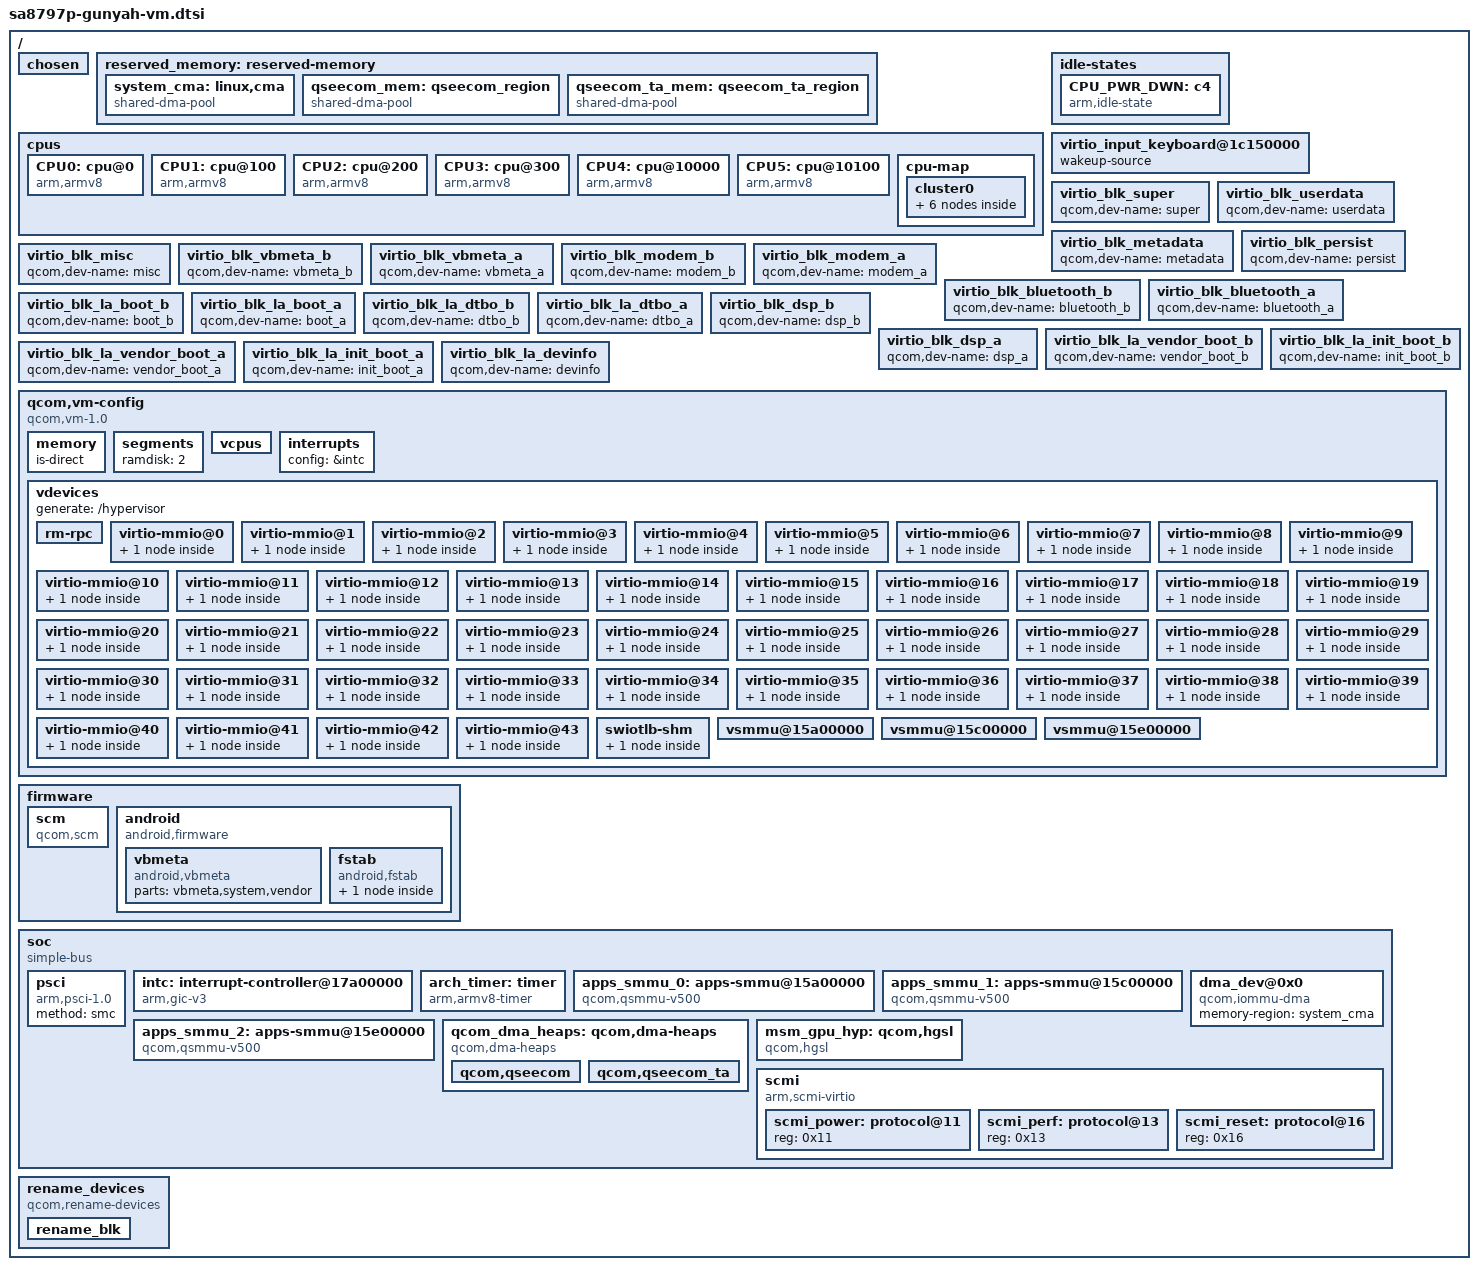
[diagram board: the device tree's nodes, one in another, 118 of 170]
#include <dt-bindings/interrupt-controller/arm-gic.h>
#include <dt-bindings/arm/msm/qcom_dma_heap_dt_constants.h>
/ {
	#address-cells = <0x2>;
	#size-cells = <0x2>;
	qcom,msm-id = <690 0x10000>, <690 0x20000>;
	interrupt-parent = <&intc>;

	chosen {
		bootargs = "console=hvc0 root=/dev/ram rw rootwait nokaslr log_buf_len=1M androidboot.force_normal_boot=1 ufshcd-core.use_mcq_mode=n kpti=0 loglevel=8 printk.devkmsg=on maxcpus=6 androidboot.verifiedbootstate=orange";
	};

	reserved_memory: reserved-memory {
		#address-cells = <2>;
		#size-cells = <2>;
		ranges;

		system_cma: linux,cma {
			compatible = "shared-dma-pool";
			alloc-ranges = <0x0 0x0 0x0 0xffffffff>;
			reusable;
			alignment = <0x0 0x400000>;
			size = <0x0 0x2000000>;
			linux,cma-default;
		};

		qseecom_mem: qseecom_region {
			compatible = "shared-dma-pool";
			alloc-ranges = <0x0 0x00000000 0x0 0xffffffff>;
			reusable;
			alignment = <0x0 0x400000>;
			size = <0x0 0x1400000>;
		};

		qseecom_ta_mem: qseecom_ta_region {
			compatible = "shared-dma-pool";
			alloc-ranges = <0x0 0x00000000 0x0 0xffffffff>;
			reusable;
			alignment = <0x0 0x400000>;
			size = <0x0 0x1000000>;
		};
	};

	cpus {
		#address-cells = <0x2>;
		#size-cells = <0x0>;

		CPU0: cpu@0 {
			compatible = "arm,armv8";
			reg = <0x0 0x0>;
			device_type = "cpu";
			enable-method = "psci";
			cpu-idle-states = <&CPU_PWR_DWN>;
		};

		CPU1: cpu@100 {
			compatible = "arm,armv8";
			reg = <0x0 0x100>;
			device_type = "cpu";
			enable-method = "psci";
			cpu-idle-states = <&CPU_PWR_DWN>;
		};

		CPU2: cpu@200 {
			compatible = "arm,armv8";
			reg = <0x0 0x200>;
			device_type = "cpu";
			enable-method = "psci";
			cpu-idle-states = <&CPU_PWR_DWN>;
		};

		CPU3: cpu@300 {
			compatible = "arm,armv8";
			reg = <0x0 0x300>;
			device_type = "cpu";
			enable-method = "psci";
			cpu-idle-states = <&CPU_PWR_DWN>;
		};

		CPU4: cpu@10000 {
			compatible = "arm,armv8";
			reg = <0x0 0x400>;
			device_type = "cpu";
			enable-method = "psci";
			cpu-idle-states = <&CPU_PWR_DWN>;
		};

		CPU5: cpu@10100 {
			compatible = "arm,armv8";
			reg = <0x0 0x500>;
			device_type = "cpu";
			enable-method = "psci";
			cpu-idle-states = <&CPU_PWR_DWN>;
		};

		cpu-map {
			cluster0 {
				core0 {
					cpu = <&CPU0>;
				};

				core1 {
					cpu = <&CPU1>;
				};

				core2 {
					cpu = <&CPU2>;
				};

				core3 {
					cpu = <&CPU3>;
				};

				core4 {
					cpu = <&CPU4>;
				};

				core5 {
					cpu = <&CPU5>;
				};
			};
		};
	};

	idle-states {
		CPU_PWR_DWN: c4 { /* C4 */
			compatible = "arm,idle-state";
			idle-state-name = "rail-pc";
			entry-latency-us = <702>;
			exit-latency-us = <1061>;
			min-residency-us = <4488>;
			arm,psci-suspend-param = <0x40000004>;
			local-timer-stop;
		};
	};

	virtio_input_keyboard@1c150000 {
		wakeup-source;
	};

	virtio_blk_super {
		qcom,dev-name = "super";
	};

	virtio_blk_userdata {
		qcom,dev-name = "userdata";
	};

	virtio_blk_metadata {
		qcom,dev-name = "metadata";
	};

	virtio_blk_persist {
		qcom,dev-name = "persist";
	};

	virtio_blk_misc {
		qcom,dev-name = "misc";
	};

	virtio_blk_vbmeta_b {
		qcom,dev-name = "vbmeta_b";
	};

	virtio_blk_vbmeta_a {
		qcom,dev-name = "vbmeta_a";
	};

	virtio_blk_modem_b {
		qcom,dev-name = "modem_b";
	};

	virtio_blk_modem_a {
		qcom,dev-name = "modem_a";
	};

	virtio_blk_bluetooth_b {
		qcom,dev-name = "bluetooth_b";
	};

	virtio_blk_bluetooth_a {
		qcom,dev-name = "bluetooth_a";
	};

	virtio_blk_la_boot_b {
		qcom,dev-name = "boot_b";
	};

	virtio_blk_la_boot_a {
		qcom,dev-name = "boot_a";
	};

	virtio_blk_la_dtbo_b {
		qcom,dev-name = "dtbo_b";
	};

	virtio_blk_la_dtbo_a {
		qcom,dev-name = "dtbo_a";
	};

	virtio_blk_dsp_b {
		qcom,dev-name = "dsp_b";
	};

	virtio_blk_dsp_a {
		qcom,dev-name = "dsp_a";
	};

	virtio_blk_la_vendor_boot_b {
		qcom,dev-name = "vendor_boot_b";
	};

	virtio_blk_la_vendor_boot_a {
		qcom,dev-name = "vendor_boot_a";
	};

	virtio_blk_la_init_boot_b {
		qcom,dev-name = "init_boot_b";
	};

	virtio_blk_la_init_boot_a {
		qcom,dev-name = "init_boot_a";
	};

	virtio_blk_la_devinfo {
		qcom,dev-name = "devinfo";
	};

	qcom,vm-config {
		compatible = "qcom,vm-1.0";
		vm-type = "aarch64-guest";
		boot-config = "fdt,unified";
		os-type = "linux";
		kernel-entry-segment = "kernel";
		kernel-entry-offset = <0x0 0x0>;
		vendor = "QTI";
		image-name = "qcom,autoghgvm";
		qcom,pasid = <0x0 0x2c>;
		qcom,qtee-config-info = "p=3,16,57,77,78,7A,7C,8F,97,159,199,47E,7F1,10C;";
		qcom,secdomain-ids = <52>;
		qcom,primary-vm-index = <0>;
		vm-attrs = "guest-ram-dump";

		memory {
			#address-cells = <0x2>;
			#size-cells = <0x0>;

			/* The IPA of the Guest regions is placed as IPA=PA */
			is-direct;
		};

		segments {
			ramdisk = <2>;
		};

		vcpus {
			config = "/cpus";
			affinity = "static";
			affinity-map = <0x5 0x4 0x3 0x2 0x1 0x0>;
			sched-priority = <0>;       /* relative to PVM */
			sched-timeslice = <5000>;   /* in ms */
		};

		interrupts {
			config = &intc;
		};

		vdevices {
			generate = "/hypervisor";

			rm-rpc {
				vdevice-type = "rm-rpc";
				generate = "/hypervisor/qcom,resource-mgr";
				console-dev;
				message-size = <0x000000f0>;
				queue-depth = <0x00000008>;
				qcom,label = <0x1>;
			};

			virtio-mmio@0 {
				vdevice-type = "virtio-mmio";
				generate = "/virtio-mmio";
				peer-default;
				vqs-num = <0x1>;
				push-compatible = "virtio,mmio";
				sync-reset;
				dma-coherent;
				dma_base = <0x0 0x0>;
				memory {
					qcom,label = <0x20>;
					#address-cells = <0x2>;
					allocate-base;
				};
			};

			virtio-mmio@1 {
				vdevice-type = "virtio-mmio";
				patch = "/virtio_blk_la_devinfo";
				peer-default;
				vqs-num = <0x1>;
				push-compatible = "virtio,mmio";
				sync-reset;
				dma-coherent;
				dma_base = <0x0 0x4000>;
				memory {
					qcom,label = <0x21>;
					#address-cells = <0x2>;
					allocate-base;
				};
			};

			virtio-mmio@2 {
				vdevice-type = "virtio-mmio";
				patch = "/virtio_blk_la_init_boot_a";
				peer-default;
				vqs-num = <0x1>;
				push-compatible = "virtio,mmio";
				sync-reset;
				dma-coherent;
				dma_base = <0x0 0x8000>;
				memory {
					qcom,label = <0x22>;
					#address-cells = <0x2>;
					allocate-base;
				};
			};

			virtio-mmio@3 {
				vdevice-type = "virtio-mmio";
				patch = "/virtio_blk_la_init_boot_b";
				peer-default;
				vqs-num = <0x1>;
				push-compatible = "virtio,mmio";
				sync-reset;
				dma-coherent;
				dma_base = <0x0 0xC000>;
				memory {
					qcom,label = <0x23>;
					#address-cells = <0x2>;
					allocate-base;
				};
			};

			virtio-mmio@4 {
				vdevice-type = "virtio-mmio";
				patch = "/virtio_blk_la_vendor_boot_a";
				peer-default;
				vqs-num = <0x1>;
				push-compatible = "virtio,mmio";
				sync-reset;
				dma-coherent;
				dma_base = <0x0 0x10000>;
				memory {
					qcom,label = <0x24>;
					#address-cells = <0x2>;
					allocate-base;
				};
			};

			virtio-mmio@5 {
				vdevice-type = "virtio-mmio";
				patch = "/virtio_blk_la_vendor_boot_b";
				peer-default;
				vqs-num = <0x1>;
				push-compatible = "virtio,mmio";
				sync-reset;
				dma-coherent;
				dma_base = <0x0 0x14000>;
				memory {
					qcom,label = <0x25>;
					#address-cells = <0x2>;
					allocate-base;
				};
			};

			virtio-mmio@6 {
				vdevice-type = "virtio-mmio";
				patch = "/virtio_blk_dsp_a";
				peer-default;
				vqs-num = <0x1>;
				push-compatible = "virtio,mmio";
				sync-reset;
				dma-coherent;
				dma_base = <0x0 0x18000>;
				memory {
					qcom,label = <0x26>;
					#address-cells = <0x2>;
					allocate-base;
				};
			};

			virtio-mmio@7 {
				vdevice-type = "virtio-mmio";
				patch = "/virtio_blk_dsp_b";
				peer-default;
				vqs-num = <0x1>;
				push-compatible = "virtio,mmio";
				sync-reset;
				dma-coherent;
				dma_base = <0x0 0x1C000>;
				memory {
					qcom,label = <0x27>;
					#address-cells = <0x2>;
					allocate-base;
				};
			};

			virtio-mmio@8 {
				vdevice-type = "virtio-mmio";
				patch = "/virtio_blk_la_dtbo_a";
				peer-default;
				vqs-num = <0x1>;
				push-compatible = "virtio,mmio";
				sync-reset;
				dma-coherent;
				dma_base = <0x0 0x20000>;
				memory {
					qcom,label = <0x28>;
					#address-cells = <0x2>;
					allocate-base;
				};
			};

			virtio-mmio@9 {
				vdevice-type = "virtio-mmio";
				patch = "/virtio_blk_la_dtbo_b";
				peer-default;
				vqs-num = <0x1>;
				push-compatible = "virtio,mmio";
				sync-reset;
				dma-coherent;
				dma_base = <0x0 0x24000>;
				memory {
					qcom,label = <0x29>;
					#address-cells = <0x2>;
					allocate-base;
				};
			};

			virtio-mmio@10 {
				vdevice-type = "virtio-mmio";
				patch = "/virtio_blk_la_boot_a";
				peer-default;
				vqs-num = <0x1>;
				push-compatible = "virtio,mmio";
				sync-reset;
				dma-coherent;
				dma_base = <0x0 0x28000>;
				memory {
					qcom,label = <0x2A>;
					#address-cells = <0x2>;
					allocate-base;
				};
			};

			virtio-mmio@11 {
				vdevice-type = "virtio-mmio";
				patch = "/virtio_blk_la_boot_b";
				peer-default;
				vqs-num = <0x1>;
				push-compatible = "virtio,mmio";
				sync-reset;
				dma-coherent;
				dma_base = <0x0 0x2C000>;
				memory {
					qcom,label = <0x2B>;
					#address-cells = <0x2>;
					allocate-base;
				};
			};

			virtio-mmio@12 {
				vdevice-type = "virtio-mmio";
				patch = "/virtio_blk_bluetooth_a";
				peer-default;
				vqs-num = <0x1>;
				push-compatible = "virtio,mmio";
				sync-reset;
				dma-coherent;
				dma_base = <0x0 0x30000>;
				memory {
					qcom,label = <0x2C>;
					#address-cells = <0x2>;
					allocate-base;
				};
			};

			virtio-mmio@13 {
				vdevice-type = "virtio-mmio";
				patch = "/virtio_blk_bluetooth_b";
				peer-default;
				vqs-num = <0x1>;
				push-compatible = "virtio,mmio";
				sync-reset;
				dma-coherent;
				dma_base = <0x0 0x34000>;
				memory {
					qcom,label = <0x2D>;
					#address-cells = <0x2>;
					allocate-base;
				};
			};

			virtio-mmio@14 {
				vdevice-type = "virtio-mmio";
				patch = "/virtio_blk_modem_a";
				peer-default;
				vqs-num = <0x1>;
				push-compatible = "virtio,mmio";
				sync-reset;
				dma-coherent;
				dma_base = <0x0 0x38000>;
				memory {
					qcom,label = <0x2E>;
					#address-cells = <0x2>;
					allocate-base;
				};
			};

			virtio-mmio@15 {
				vdevice-type = "virtio-mmio";
				patch = "/virtio_blk_modem_b";
				peer-default;
				vqs-num = <0x1>;
				push-compatible = "virtio,mmio";
				sync-reset;
				dma-coherent;
				dma_base = <0x0 0x3C000>;
				memory {
					qcom,label = <0x2F>;
					#address-cells = <0x2>;
					allocate-base;
				};
			};

			virtio-mmio@16 {
				vdevice-type = "virtio-mmio";
				patch = "/virtio_blk_vbmeta_a";
				peer-default;
				vqs-num = <0x1>;
				push-compatible = "virtio,mmio";
				sync-reset;
				dma-coherent;
				dma_base = <0x0 0x40000>;
				memory {
					qcom,label = <0x30>;
					#address-cells = <0x2>;
					allocate-base;
				};
			};

			virtio-mmio@17 {
				vdevice-type = "virtio-mmio";
				patch = "/virtio_blk_vbmeta_b";
				peer-default;
				vqs-num = <0x1>;
				push-compatible = "virtio,mmio";
				sync-reset;
				dma-coherent;
				dma_base = <0x0 0x44000>;
				memory {
					qcom,label = <0x31>;
					#address-cells = <0x2>;
					allocate-base;
				};
			};

			virtio-mmio@18 {
				vdevice-type = "virtio-mmio";
				patch = "/virtio_blk_misc";
				peer-default;
				vqs-num = <0x1>;
				push-compatible = "virtio,mmio";
				sync-reset;
				dma-coherent;
				dma_base = <0x0 0x48000>;
				memory {
					qcom,label = <0x32>;
					#address-cells = <0x2>;
					allocate-base;
				};
			};

			virtio-mmio@19 {
				vdevice-type = "virtio-mmio";
				patch = "/virtio_blk_persist";
				peer-default;
				vqs-num = <0x1>;
				push-compatible = "virtio,mmio";
				sync-reset;
				dma-coherent;
				dma_base = <0x0 0x4C000>;
				memory {
					qcom,label = <0x33>;
					#address-cells = <0x2>;
					allocate-base;
				};
			};

			virtio-mmio@20 {
				vdevice-type = "virtio-mmio";
				patch = "/virtio_blk_metadata";
				peer-default;
				vqs-num = <0x1>;
				push-compatible = "virtio,mmio";
				sync-reset;
				dma-coherent;
				dma_base = <0x0 0x50000>;
				memory {
					qcom,label = <0x34>;
					#address-cells = <0x2>;
					allocate-base;
				};
			};

			virtio-mmio@21 {
				vdevice-type = "virtio-mmio";
				patch = "/virtio_blk_userdata";
				peer-default;
				vqs-num = <0x1>;
				push-compatible = "virtio,mmio";
				sync-reset;
				dma-coherent;
				dma_base = <0x0 0x54000>;
				memory {
					qcom,label = <0x35>;
					#address-cells = <0x2>;
					allocate-base;
				};
			};

			virtio-mmio@22 {
				vdevice-type = "virtio-mmio";
				patch = "/virtio_blk_super";
				peer-default;
				vqs-num = <0x1>;
				push-compatible = "virtio,mmio";
				sync-reset;
				dma-coherent;
				dma_base = <0x0 0x58000>;
				memory {
					qcom,label = <0x36>;
					#address-cells = <0x2>;
					allocate-base;
				};
			};

			/* Virtio net 0 device */
			virtio-mmio@23 {
				vdevice-type = "virtio-mmio";
				generate = "/virtio-mmio";
				peer-default;
				vqs-num = <0x2>;
				push-compatible = "virtio,mmio";
				sync-reset;
				dma-coherent;
				dma_base = <0x0 0x5C000>;
				memory {
					qcom,label = <0x37>;
					#address-cells = <0x2>;
					allocate-base;
				};
			};

			/* Virtio net 1 device */
			virtio-mmio@24 {
				vdevice-type = "virtio-mmio";
				generate = "/virtio-mmio";
				peer-default;
				vqs-num = <0x2>;
				push-compatible = "virtio,mmio";
				sync-reset;
				dma-coherent;
				dma_base = <0x0 0x64000>;
				memory {
					qcom,label = <0x38>;
					#address-cells = <0x2>;
					allocate-base;
				};
			};

			/* HAB 0 device */
			virtio-mmio@25 {
				vdevice-type = "virtio-mmio";
				generate = "/virtio-mmio";
				peer-default;
				vqs-num = <0x2>;
				push-compatible = "virtio,mmio";
				sync-reset;
				dma-coherent;
				dma_base = <0x0 0x6C000>;
				memory {
					qcom,label = <0x39>;
					#address-cells = <0x2>;
					allocate-base;
				};
			};

			/* HAB 1 device */
			virtio-mmio@26 {
				vdevice-type = "virtio-mmio";
				generate = "/virtio-mmio";
				peer-default;
				vqs-num = <0x2>;
				push-compatible = "virtio,mmio";
				sync-reset;
				dma-coherent;
				dma_base = <0x0 0x7C000>;
				memory {
					qcom,label = <0x3A>;
					#address-cells = <0x2>;
					allocate-base;
				};
			};

			/* HAB 2 device */
			virtio-mmio@27 {
				vdevice-type = "virtio-mmio";
				generate = "/virtio-mmio";
				peer-default;
				vqs-num = <0x8>;
				push-compatible = "virtio,mmio";
				sync-reset;
				dma-coherent;
				dma_base = <0x0 0x8C000>;
				memory {
					qcom,label = <0x3B>;
					#address-cells = <0x2>;
					allocate-base;
				};
			};

			/* HAB 3 device */
			virtio-mmio@28 {
				vdevice-type = "virtio-mmio";
				generate = "/virtio-mmio";
				peer-default;
				vqs-num = <0xA>;
				push-compatible = "virtio,mmio";
				sync-reset;
				dma-coherent;
				dma_base = <0x0 0xCC000>;
				memory {
					qcom,label = <0x3C>;
					#address-cells = <0x2>;
					allocate-base;
				};
			};

			/* HAB 4 device */
			virtio-mmio@29 {
				vdevice-type = "virtio-mmio";
				generate = "/virtio-mmio";
				peer-default;
				vqs-num = <0x6>;
				push-compatible = "virtio,mmio";
				sync-reset;
				dma-coherent;
				dma_base = <0x0 0x11C000>;
				memory {
					qcom,label = <0x3D>;
					#address-cells = <0x2>;
					allocate-base;
				};
			};

			/* HAB 5 device */
			virtio-mmio@30 {
				vdevice-type = "virtio-mmio";
				generate = "/virtio-mmio";
				peer-default;
				vqs-num = <0x6>;
				push-compatible = "virtio,mmio";
				sync-reset;
				dma-coherent;
				dma_base = <0x0 0x14C000>;
				memory {
					qcom,label = <0x3E>;
					#address-cells = <0x2>;
					allocate-base;
				};
			};

			/* Virtio input 0 device */
			virtio-mmio@31 {
				vdevice-type = "virtio-mmio";
				generate = "/virtio-mmio";
				virtio,device-type = <18>;
				peer-default;
				vqs-num = <0x2>;
				push-compatible = "virtio,mmio";
				sync-reset;
				dma-coherent;
				dma_base = <0x0 0x17C000>;
				memory {
					qcom,label = <0x3F>;
					#address-cells = <0x2>;
					allocate-base;
				};
			};

			/* Virtio input 1 device */
			virtio-mmio@32 {
				vdevice-type = "virtio-mmio";
				generate = "/virtio-mmio";
				virtio,device-type = <18>;
				peer-default;
				vqs-num = <0x2>;
				push-compatible = "virtio,mmio";
				sync-reset;
				dma-coherent;
				dma_base = <0x0 0x180000>;
				memory {
					qcom,label = <0x40>;
					#address-cells = <0x2>;
					allocate-base;
				};
			};

			/* Virtio console device */
			virtio-mmio@33 {
				vdevice-type = "virtio-mmio";
				generate = "/virtio-mmio";
				peer-default;
				vqs-num = <0x2>;
				push-compatible = "virtio,mmio";
				sync-reset;
				dma-coherent;
				dma_base = <0x0 0x184000>;
				memory {
					qcom,label = <0x41>;
					#address-cells = <0x2>;
					allocate-base;
				};
			};

			/* Virtio SCMI device */
			virtio-mmio@34 {
				vdevice-type = "virtio-mmio";
				generate = "/virtio-mmio";
				peer-default;
				vqs-num = <0x2>;
				push-compatible = "virtio,mmio";
				sync-reset;
				dma-coherent;
				dma_base = <0x0 0x18C000>;
				memory {
					qcom,label = <0x42>;
					#address-cells = <0x2>;
					allocate-base;
				};
			};

			/* Virtio vsock device */
			virtio-mmio@35 {
				vdevice-type = "virtio-mmio";
				generate = "/virtio-mmio";
				peer-default;
				vqs-num = <0x3>;
				push-compatible = "virtio,mmio";
				sync-reset;
				dma-coherent;
				dma_base = <0x0 0x194000>;
				memory {
					qcom,label = <0x43>;
					#address-cells = <0x2>;
					allocate-base;
				};
			};

			/* Virtio glink device */
			virtio-mmio@36 {
				vdevice-type = "virtio-mmio";
				generate = "/virtio-mmio";
				peer-default;
				vqs-num = <0x1>;
				push-compatible = "virtio,mmio";
				sync-reset;
				dma-coherent;
				dma_base = <0x0 0x1A0000>;
				memory {
					qcom,label = <0x44>;
					#address-cells = <0x2>;
					allocate-base;
				};
			};

			/* Virtio FastRPC device */
			virtio-mmio@37 {
				vdevice-type = "virtio-mmio";
				generate = "/virtio-mmio";
				peer-default;
				vqs-num = <0x2>;
				push-compatible = "virtio,mmio";
				sync-reset;
				dma-coherent;
				dma_base = <0x0 0x1A2000>;
				memory {
					qcom,label = <0x45>;
					#address-cells = <0x2>;
					allocate-base;
				};
			};

			/* Virtio I2C device */
			virtio-mmio@38 {
				vdevice-type = "virtio-mmio";
				generate = "/virtio-mmio";
				peer-default;
				vqs-num = <0x1>;
				push-compatible = "virtio,mmio";
				sync-reset;
				dma-coherent;
				dma_base = <0x0 0x1A6000>;
				memory {
					qcom,label = <0x46>;
					#address-cells = <0x2>;
					allocate-base;
				};
			};

			/* Virtio SSR device */
			virtio-mmio@39 {
				vdevice-type = "virtio-mmio";
				generate = "/virtio-mmio";
				peer-default;
				vqs-num = <0x1>;
				push-compatible = "virtio,mmio";
				sync-reset;
				dma-coherent;
				dma_base = <0x0 0x1A8000>;
				memory {
					qcom,label = <0x47>;
					#address-cells = <0x2>;
					allocate-base;
				};
			};

			/* VHAB 6 device */
			virtio-mmio@40 {
				vdevice-type = "virtio-mmio";
				generate = "/virtio-mmio";
				peer-default;
				vqs-num = <0x2>;
				push-compatible = "virtio,mmio";
				sync-reset;
				dma-coherent;
				dma_base = <0x0 0x1AA000>;
				memory {
					qcom,label = <0x48>;
					#address-cells = <0x2>;
					allocate-base;
				};
			};

			/* VHAB 7 device */
			virtio-mmio@41 {
				vdevice-type = "virtio-mmio";
				generate = "/virtio-mmio";
				peer-default;
				vqs-num = <0x2>;
				push-compatible = "virtio,mmio";
				sync-reset;
				dma-coherent;
				dma_base = <0x0 0x1BA000>;
				memory {
					qcom,label = <0x49>;
					#address-cells = <0x2>;
					allocate-base;
				};
			};

			/* VHAB 8 device */
			virtio-mmio@42 {
				vdevice-type = "virtio-mmio";
				generate = "/virtio-mmio";
				peer-default;
				vqs-num = <0x6>;
				push-compatible = "virtio,mmio";
				sync-reset;
				dma-coherent;
				dma_base = <0x0 0x1CA000>;
				memory {
					qcom,label = <0x4A>;
					#address-cells = <0x2>;
					allocate-base;
				};
			};
			/* Reserved device */
			virtio-mmio@43 {
				vdevice-type = "virtio-mmio";
				generate = "/virtio-mmio";
				peer-default;
				vqs-num = <0x2>;
				push-compatible = "virtio,mmio";
				sync-reset;
				dma-coherent;
				dma_base = <0x0 0x1A0000>;
				memory {
					qcom,label = <0x4B>;
					#address-cells = <0x2>;
					allocate-base;
				};
			};

			swiotlb-shm {
				vdevice-type = "shm";
				generate = "/swiotlb";
				push-compatible = "swiotlb";
				peer-default;
				dma_base = <0x0 0x200000>;
				memory {
					qcom,label = <0x50>;
					#address-cells = <0x2>;
					allocate-base;
				};
			};

			vsmmu@15a00000 {
				vdevice-type = "vsmmu-v2";
				smmu-handle = <0x15a00000>;
				num-cbs = <0x8>;
				num-smrs = <0x8>;
				patch = "/soc/apps-smmu@15a00000";
			};

			vsmmu@15c00000 {
				vdevice-type = "vsmmu-v2";
				smmu-handle = <0x15c00000>;
				num-cbs = <0x8>;
				num-smrs = <0x8>;
				patch = "/soc/apps-smmu@15c00000";
			};

			vsmmu@15e00000 {
				vdevice-type = "vsmmu-v2";
				smmu-handle = <0x15e00000>;
				num-cbs = <0x8>;
				num-smrs = <0x8>;
				patch = "/soc/apps-smmu@15e00000";
			};
		};
	};

	firmware: firmware {
		scm {
			compatible = "qcom,scm";
		};

		android {
			compatible = "android,firmware";
			boot_devices = "70002000.virtio_blk_la_devinfo,70003000.virtio_blk_la_init_boot_a,70004000.virtio_blk_la_init_boot_b,70005000.virtio_blk_la_vendor_boot_a,70006000.virtio_blk_la_vendor_boot_b,70007000.virtio_blk_dsp_a,70008000.virtio_blk_dsp_b,70009000.virtio_blk_la_dtbo_a,7000a000.virtio_blk_la_dtbo_b,7000b000.virtio_blk_la_boot_a,7000c000.virtio_blk_la_boot_b,7000d000.virtio_blk_bluetooth_a,7000e000.virtio_blk_bluetooth_b,7000f000.virtio_blk_modem_a,70010000.virtio_blk_modem_b,70011000.virtio_blk_vbmeta_a,70012000.virtio_blk_vbmeta_b,70013000.virtio_blk_misc,70014000.virtio_blk_persist,70015000.virtio_blk_metadata,70016000.virtio_blk_userdata,70017000.virtio_blk_super";

			vbmeta {
				compatible = "android,vbmeta";
				parts = "vbmeta,system,vendor";
			};

			fstab {
				compatible = "android,fstab";
				vendor {
					compatible = "android,vendor";
					dev="/dev/block/platform/vdevs/1c0f0000.virtio_blk/vdc";
					type = "ext4";
					mnt_flags = "ro,barrier=1,discard";
					fsmgr_flags = "wait";
					status = "disabled";
				};
			};
		};
	};

	soc: soc { };
};

&soc {
	#address-cells = <1>;
	#size-cells = <1>;
	ranges = <0 0 0 0xffffffff>;
	compatible = "simple-bus";

	psci {
		compatible = "arm,psci-1.0";
		method = "smc";
	};

	intc: interrupt-controller@17a00000 {
		compatible = "arm,gic-v3";
		interrupt-controller;
		#interrupt-cells = <0x3>;
		#redistributor-regions = <1>;
		redistributor-stride = <0x0 0x20000>;
		reg = <0x17a00000 0x10000>,     /* GICD */
		      <0x17a60000 0x100000>;    /* GICR * 8 */
	};

	arch_timer: timer {
		compatible = "arm,armv8-timer";
		always-on;
		interrupts = <GIC_PPI 13 (GIC_CPU_MASK_SIMPLE(8) | IRQ_TYPE_LEVEL_LOW)>,
			     <GIC_PPI 14 (GIC_CPU_MASK_SIMPLE(8) | IRQ_TYPE_LEVEL_LOW)>,
			     <GIC_PPI 11 (GIC_CPU_MASK_SIMPLE(8) | IRQ_TYPE_LEVEL_LOW)>,
			     <GIC_PPI 12 (GIC_CPU_MASK_SIMPLE(8) | IRQ_TYPE_LEVEL_LOW)>;
		clock-frequency = <19200000>;
	};

	apps_smmu_0: apps-smmu@15a00000 {
		/*
		 * reg, #global-interrupts & interrupts  properties will
		 * be added dynamically by bootloader.
		 */
		compatible = "qcom,qsmmu-v500", "qcom,virt-smmu";
		#iommu-cells = <2>;
		qcom,use-3-lvl-tables;
		dma-coherent;
	};

	apps_smmu_1: apps-smmu@15c00000 {
		/*
		 * reg, #global-interrupts & interrupts  properties will
		 * be added dynamically by bootloader.
		 */
		compatible = "qcom,qsmmu-v500", "qcom,virt-smmu";
		#iommu-cells = <2>;
		qcom,use-3-lvl-tables;
		dma-coherent;
	};

	apps_smmu_2: apps-smmu@15e00000 {
		/*
		 * reg, #global-interrupts & interrupts  properties will
		 * be added dynamically by bootloader.
		 */
		compatible = "qcom,qsmmu-v500", "qcom,virt-smmu";
		#iommu-cells = <2>;
		qcom,use-3-lvl-tables;
		dma-coherent;
	};

	qcom_dma_heaps: qcom,dma-heaps {
		compatible = "qcom,dma-heaps";

		qcom,qseecom {
			qcom,dma-heap-name = "qcom,qseecom";
			qcom,dma-heap-type = <HEAP_TYPE_CMA>;
			memory-region = <&qseecom_mem>;
		};

		qcom,qseecom_ta {
			qcom,dma-heap-name = "qcom,qseecom-ta";
			qcom,dma-heap-type = <HEAP_TYPE_CMA>;
			memory-region = <&qseecom_ta_mem>;
		};
	};

	dma_dev@0x0 {
		compatible = "qcom,iommu-dma";
		memory-region = <&system_cma>;
	};

	msm_gpu_hyp: qcom,hgsl {
		compatible = "qcom,hgsl";

		default_iocoherency;
		db-off;
	};

	scmi {
		compatible = "arm,scmi-virtio";
		#address-cells = <1>;
		#size-cells = <0>;
		status = "ok";

		scmi_power: protocol@11 {
			reg = <0x11>;
			#power-domain-cells = <1>;
		};

		scmi_perf: protocol@13 {
			reg = <0x13>;
			#power-domain-cells = <1>;
		};

		scmi_reset: protocol@16 {
			reg = <0x16>;
			#reset-cells = <1>;
		};
	};
};

/ {
	rename_devices: rename_devices {
		compatible = "qcom,rename-devices";
		rename_blk: rename_blk {
			device-type = "block";
			actual-dev =    "vda", "vdb", "vdc",
					"vdd", "vde", "vdf",
					"vdg", "vdh", "vdi",
					"vdj", "vdk", "vdl",
					"vdm", "vdn", "vdo",
					"vdp", "vdq", "vdr",
					"vds", "vdt", "vdu", "vdv";
			rename-dev = "super", "userdata", "metadata",
					"persist", "misc", "vbmeta_b",
					"vbmeta_a", "modem_b", "modem_a",
					"bluetooth_b", "bluetooth_a",
					"boot_b", "boot_a", "dtbo_b",
					"dtbo_a", "dsp_b", "dsp_a",
					"vendor_boot_b", "vendor_boot_a",
					"init_boot_b", "init_boot_a", "devinfo";
		};
	};
};

